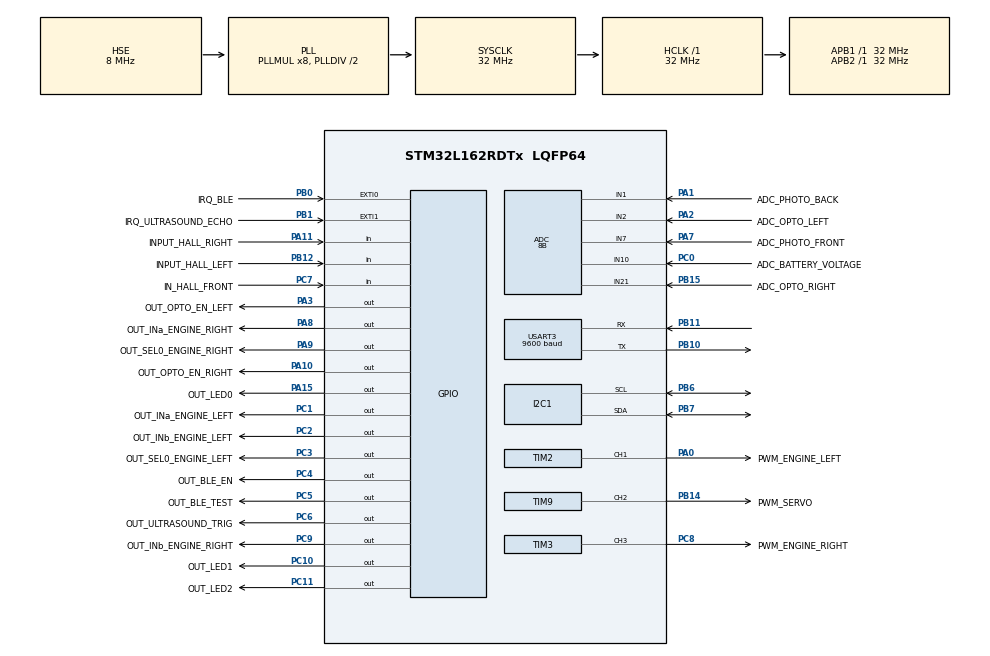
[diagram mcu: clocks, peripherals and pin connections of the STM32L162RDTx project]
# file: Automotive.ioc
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ADC.Channel-0\#ChannelRegularConversion=ADC_CHANNEL_1
ADC.NbrOfConversionFlag=1
ADC.Rank-0\#ChannelRegularConversion=1
ADC.Resolution=ADC_RESOLUTION_8B
ADC.SamplingTime-0\#ChannelRegularConversion=ADC_SAMPLETIME_4CYCLES
Dma.Request0=USART3_RX
Dma.Request1=USART3_TX
Dma.USART3_RX.0.Direction=DMA_PERIPH_TO_MEMORY
Dma.USART3_RX.0.Instance=DMA1_Channel3
Dma.USART3_RX.0.MemDataAlignment=DMA_MDATAALIGN_BYTE
Dma.USART3_RX.0.MemInc=DMA_MINC_ENABLE
Dma.USART3_RX.0.Mode=DMA_NORMAL
Dma.USART3_RX.0.PeriphDataAlignment=DMA_PDATAALIGN_BYTE
Dma.USART3_RX.0.PeriphInc=DMA_PINC_DISABLE
Dma.USART3_RX.0.Priority=DMA_PRIORITY_VERY_HIGH
Dma.USART3_TX.1.Direction=DMA_MEMORY_TO_PERIPH
Dma.USART3_TX.1.Instance=DMA1_Channel2
Dma.USART3_TX.1.MemDataAlignment=DMA_MDATAALIGN_BYTE
Dma.USART3_TX.1.MemInc=DMA_MINC_ENABLE
Dma.USART3_TX.1.Mode=DMA_NORMAL
Dma.USART3_TX.1.PeriphDataAlignment=DMA_PDATAALIGN_BYTE
Dma.USART3_TX.1.PeriphInc=DMA_PINC_DISABLE
Dma.USART3_TX.1.Priority=DMA_PRIORITY_LOW
FREERTOS.INCLUDE_xEventGroupSetBitFromISR=1
FREERTOS.Tasks01=defaultTask,24,128,StartDefaultTask,Default,NULL,Dynamic,NULL,NULL
FREERTOS.configCHECK_FOR_STACK_OVERFLOW=1
FREERTOS.configTOTAL_HEAP_SIZE=10240
FREERTOS.configUSE_DAEMON_TASK_STARTUP_HOOK=1
FREERTOS.configUSE_IDLE_HOOK=1
FREERTOS.configUSE_MALLOC_FAILED_HOOK=1
FREERTOS.configUSE_TICK_HOOK=1
I2C1.I2C_Mode=I2C_Standard
Mcu.Family=STM32L1
Mcu.Name=STM32L162RDTx
Mcu.Package=LQFP64
NVIC.ADC1_IRQn=true\:5\:0\:false\:false\:true\:true\:true\:true
NVIC.DMA1_Channel2_IRQn=true\:6\:0\:true\:false\:true\:true\:false\:true
NVIC.DMA1_Channel3_IRQn=true\:5\:0\:true\:false\:true\:true\:false\:true
NVIC.EXTI0_IRQn=true\:5\:0\:true\:false\:true\:true\:true\:true
NVIC.EXTI1_IRQn=true\:5\:0\:true\:false\:true\:true\:true\:true
NVIC.PriorityGroup=NVIC_PRIORITYGROUP_4
NVIC.TIM10_IRQn=true\:5\:0\:true\:false\:true\:true\:true\:true
NVIC.TIM5_IRQn=true\:0\:0\:false\:false\:true\:false\:false\:true
NVIC.TimeBase=TIM5_IRQn
NVIC.TimeBaseIP=TIM5
PA0-WKUP1.GPIO_Label=PWM_ENGINE_LEFT
PA0-WKUP1.Signal=S_TIM2_CH1_ETR
PA1.GPIO_Label=ADC_PHOTO_BACK
PA1.Mode=IN1
PA1.Signal=ADC_IN1
PA10.GPIO_Label=OUT_OPTO_EN_RIGHT
PA10.Signal=GPIO_Output
PA11.GPIO_Label=INPUT_HALL_RIGHT
PA11.Signal=GPIO_Input
PA13.Signal=SYS_JTMS-SWDIO
PA14.Signal=SYS_JTCK-SWCLK
PA15.GPIO_Label=OUT_LED0
PA15.Signal=GPIO_Output
PA2.GPIO_Label=ADC_OPTO_LEFT
PA2.Mode=IN2
PA2.Signal=ADC_IN2
PA3.GPIO_Label=OUT_OPTO_EN_LEFT
PA3.Signal=GPIO_Output
PA7.GPIO_Label=ADC_PHOTO_FRONT
PA7.Mode=IN7
PA7.Signal=ADC_IN7
PA8.GPIO_Label=OUT_INa_ENGINE_RIGHT
PA8.Signal=GPIO_Output
PA9.GPIO_Label=OUT_SEL0_ENGINE_RIGHT
PA9.Signal=GPIO_Output
PB0.GPIO_Label=IRQ_BLE
PB0.Signal=GPXTI0
PB1.GPIO_Label=IRQ_ULTRASOUND_ECHO
PB1.GPIO_ModeDefaultEXTI=GPIO_MODE_IT_RISING_FALLING
PB1.GPIO_PuPd=GPIO_NOPULL
PB1.Signal=GPXTI1
PB10.Mode=Asynchronous
PB10.Signal=USART3_TX
PB11.Mode=Asynchronous
PB11.Signal=USART3_RX
PB12.GPIO_Label=INPUT_HALL_LEFT
PB12.Signal=GPIO_Input
PB14.GPIO_Label=PWM_SERVO
PB14.Signal=S_TIM9_CH2
PB15.GPIO_Label=ADC_OPTO_RIGHT
PB15.Mode=IN21
PB15.Signal=ADC_IN21
PB6.Mode=I2C
PB6.Signal=I2C1_SCL
PB7.Mode=I2C
PB7.Signal=I2C1_SDA
PC0.GPIO_Label=ADC_BATTERY_VOLTAGE
PC0.Mode=IN10
PC0.Signal=ADC_IN10
PC1.GPIO_Label=OUT_INa_ENGINE_LEFT
PC1.Signal=GPIO_Output
PC10.GPIO_Label=OUT_LED1
PC10.Signal=GPIO_Output
PC11.GPIO_Label=OUT_LED2
PC11.Signal=GPIO_Output
PC2.GPIO_Label=OUT_INb_ENGINE_LEFT
PC2.Signal=GPIO_Output
PC3.GPIO_Label=OUT_SEL0_ENGINE_LEFT
PC3.Signal=GPIO_Output
PC4.GPIO_Label=OUT_BLE_EN
PC4.PinState=GPIO_PIN_SET
PC4.Signal=GPIO_Output
PC5.GPIO_Label=OUT_BLE_TEST
PC5.GPIO_PuPd=GPIO_NOPULL
PC5.Signal=GPIO_Output
PC6.GPIO_Label=OUT_ULTRASOUND_TRIG
PC6.Signal=GPIO_Output
PC7.GPIO_Label=IN_HALL_FRONT
PC7.Signal=GPIO_Input
PC8.GPIO_Label=PWM_ENGINE_RIGHT
PC8.Signal=S_TIM3_CH3
PC9.GPIO_Label=OUT_INb_ENGINE_RIGHT
PC9.Signal=GPIO_Output
PH0-OSC_IN.Mode=HSE-External-Oscillator
PH0-OSC_IN.Signal=RCC_OSC_IN
PH1-OSC_OUT.Mode=HSE-External-Oscillator
PH1-OSC_OUT.Signal=RCC_OSC_OUT
ProjectManager.HeapSize=0x200
ProjectManager.StackSize=0x400
ProjectManager.TargetToolchain=STM32CubeIDE
RCC.48MHZClocksFreq_Value=32000000
RCC.AHBFreq_Value=32000000
RCC.APB1Freq_Value=32000000
RCC.APB1TimFreq_Value=32000000
RCC.APB2Freq_Value=32000000
RCC.APB2TimFreq_Value=32000000
RCC.HCLKFreq_Value=32000000
RCC.HSE_VALUE=8000000
RCC.HSI_VALUE=16000000
RCC.LSE_VALUE=32768
RCC.MSI_VALUE=2097000
RCC.PLLMUL=RCC_PLL_MUL8
RCC.PLLSourceVirtual=RCC_PLLSOURCE_HSE
RCC.SYSCLKFreq_VALUE=32000000
RCC.SYSCLKSource=RCC_SYSCLKSOURCE_PLLCLK
RCC.VCOOutputFreq_Value=64000000
SH.S_TIM2_CH1_ETR.0=TIM2_CH1,PWM Generation1 CH1
SH.S_TIM3_CH3.0=TIM3_CH3,PWM Generation3 CH3
SH.S_TIM9_CH2.0=TIM9_CH2,PWM Generation2 CH2
TIM10.Period=1599
TIM2.AutoReloadPreload=TIM_AUTORELOAD_PRELOAD_ENABLE
TIM2.Channel-PWM\ Generation1\ CH1=TIM_CHANNEL_1
TIM2.OCFastMode_PWM-PWM\ Generation1\ CH1=TIM_OCFAST_ENABLE
TIM2.Period=3199
TIM2.Prescaler=0
TIM2.Pulse-PWM\ Generation1\ CH1=1599
TIM3.AutoReloadPreload=TIM_AUTORELOAD_PRELOAD_ENABLE
TIM3.Channel-PWM\ Generation3\ CH3=TIM_CHANNEL_3
TIM3.OCFastMode_PWM-PWM\ Generation3\ CH3=TIM_OCFAST_ENABLE
TIM3.Period=3200-1
TIM3.Pulse-PWM\ Generation3\ CH3=1500
TIM4.Period=39999
TIM4.Prescaler=3
TIM9.AutoReloadPreload=TIM_AUTORELOAD_PRELOAD_ENABLE
TIM9.Channel-PWM\ Generation2\ CH2=TIM_CHANNEL_2
TIM9.ClockDivision=TIM_CLOCKDIVISION_DIV1
TIM9.OCMode_PWM-PWM\ Generation2\ CH2=TIM_OCMODE_PWM1
TIM9.Period=3200
TIM9.Prescaler=0
TIM9.Pulse-PWM\ Generation2\ CH2=1500
USART3.BaudRate=9600
USART3.VirtualMode=VM_ASYNC
VP_FREERTOS_VS_CMSIS_V2.Mode=CMSIS_V2
VP_SYS_VS_tim5.Mode=TIM5
VP_TIM10_VS_ClockSourceINT.Mode=Internal
VP_TIM2_VS_ClockSourceINT.Mode=Internal
VP_TIM3_VS_ClockSourceINT.Mode=Internal
VP_TIM4_VS_ClockSourceINT.Mode=Internal
VP_TIM9_VS_ClockSourceINT.Mode=Internal
board=custom

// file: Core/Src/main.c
/* USER CODE BEGIN Header */
/**
 ******************************************************************************
 * @file           : main.c
 * @brief          : Main program body
 ******************************************************************************
 * @attention
 *
 * <h2><center>&copy; Copyright (c) 2021 STMicroelectronics.
 * All rights reserved.</center></h2>
 *
 * This software component is licensed by ST under Ultimate Liberty license
 * SLA0044, the "License"; You may not use this file except in compliance with
 * the License. You may obtain a copy of the License at:
 *                             www.st.com/SLA0044
 *
 ******************************************************************************
 */
/* USER CODE END Header */

#include "main.h"
#include "cmsis_os.h"
#include "adc.h"
#include "dma.h"
#include "i2c.h"
#include "tim.h"
#include "usart.h"
#include "gpio.h"

/* USER CODE BEGIN Includes */
#include "device_init.h"
#include "h_bridge.h"
/* USER CODE END Includes */

void SystemClock_Config(void);
void MX_FREERTOS_Init(void);

int main(void)
{

  /* MCU Configuration--------------------------------------------------------*/

  /* Reset of all peripherals, Initializes the Flash interface and the Systick. */
  HAL_Init();

  /* Configure the system clock */
  SystemClock_Config();

  /* Initialize all configured peripherals */
  MX_GPIO_Init();
  MX_DMA_Init();
  MX_ADC_Init();
  MX_I2C1_Init();
  MX_TIM2_Init();
  MX_TIM3_Init();
  MX_TIM9_Init();
  MX_USART3_UART_Init();
  MX_TIM4_Init();
  MX_TIM10_Init();
  /* USER CODE BEGIN 2 */
	device_init();
	h_bridge_init();
  /* USER CODE END 2 */

  /* Init scheduler */
  osKernelInitialize();  /* Call init function for freertos objects (in freertos.c) */
  MX_FREERTOS_Init();
  /* Start scheduler */
  osKernelStart();

  /* We should never get here as control is now taken by the scheduler */
  /* Infinite loop */
	while (1) {

	}
}

void SystemClock_Config(void)
{
  RCC_OscInitTypeDef RCC_OscInitStruct = {0};
  RCC_ClkInitTypeDef RCC_ClkInitStruct = {0};

  /** Configure the main internal regulator output voltage
  */
  __HAL_PWR_VOLTAGESCALING_CONFIG(PWR_REGULATOR_VOLTAGE_SCALE1);
  /** Initializes the CPU, AHB and APB busses clocks
  */
  RCC_OscInitStruct.OscillatorType = RCC_OSCILLATORTYPE_HSI|RCC_OSCILLATORTYPE_HSE;
  RCC_OscInitStruct.HSEState = RCC_HSE_ON;
  RCC_OscInitStruct.HSIState = RCC_HSI_ON;
  RCC_OscInitStruct.HSICalibrationValue = RCC_HSICALIBRATION_DEFAULT;
  RCC_OscInitStruct.PLL.PLLState = RCC_PLL_ON;
  RCC_OscInitStruct.PLL.PLLSource = RCC_PLLSOURCE_HSE;
  RCC_OscInitStruct.PLL.PLLMUL = RCC_PLL_MUL8;
  RCC_OscInitStruct.PLL.PLLDIV = RCC_PLL_DIV2;
  if (HAL_RCC_OscConfig(&RCC_OscInitStruct) != HAL_OK)
  {
    Error_Handler();
  }
  /** Initializes the CPU, AHB and APB busses clocks
  */
  RCC_ClkInitStruct.ClockType = RCC_CLOCKTYPE_HCLK|RCC_CLOCKTYPE_SYSCLK
                              |RCC_CLOCKTYPE_PCLK1|RCC_CLOCKTYPE_PCLK2;
  RCC_ClkInitStruct.SYSCLKSource = RCC_SYSCLKSOURCE_PLLCLK;
  RCC_ClkInitStruct.AHBCLKDivider = RCC_SYSCLK_DIV1;
  RCC_ClkInitStruct.APB1CLKDivider = RCC_HCLK_DIV1;
  RCC_ClkInitStruct.APB2CLKDivider = RCC_HCLK_DIV1;

  if (HAL_RCC_ClockConfig(&RCC_ClkInitStruct, FLASH_LATENCY_1) != HAL_OK)
  {
    Error_Handler();
  }
}

 /**
  * @brief  Period elapsed callback in non blocking mode
  * @note   This function is called  when TIM5 interrupt took place, inside
  * HAL_TIM_IRQHandler(). It makes a direct call to HAL_IncTick() to increment
  * a global variable "uwTick" used as application time base.
  * @param  htim : TIM handle
  * @retval None
  */
void HAL_TIM_PeriodElapsedCallback(TIM_HandleTypeDef *htim)
{
  if (htim->Instance == TIM5) {
    HAL_IncTick();
  }
  /* USER CODE BEGIN Callback 1 */

  // also the code for others timers if overflow :)

  // when tim10
  if(htim->Instance == TIM10) {
	  // clear pin ultrasound trigger
	  HAL_GPIO_WritePin(OUT_ULTRASOUND_TRIG_GPIO_Port, OUT_ULTRASOUND_TRIG_Pin, GPIO_PIN_RESET);
	  // and this is it
  }

  /* USER CODE END Callback 1 */
}

void Error_Handler(void)
{
}

/************************ (C) COPYRIGHT STMicroelectronics *****END OF FILE****/

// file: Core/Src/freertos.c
/* USER CODE BEGIN Header */
/**
  ******************************************************************************
  * File Name          : freertos.c
  * Description        : Code for freertos applications
  ******************************************************************************
  * @attention
  *
  * <h2><center>&copy; Copyright (c) 2021 STMicroelectronics.
  * All rights reserved.</center></h2>
  *
  * This software component is licensed by ST under Ultimate Liberty license
  * SLA0044, the "License"; You may not use this file except in compliance with
  * the License. You may obtain a copy of the License at:
  *                             www.st.com/SLA0044
  *
  ******************************************************************************
  */
/* USER CODE END Header */

#include "FreeRTOS.h"
#include "task.h"
#include "main.h"
#include "cmsis_os.h"

/* USER CODE BEGIN Includes */
#include "runtime.h"
/* USER CODE END Includes */

/* Definitions for defaultTask */
osThreadId_t defaultTaskHandle;
const osThreadAttr_t defaultTask_attributes = {
  .name = "defaultTask",
  .priority = (osPriority_t) osPriorityNormal,
  .stack_size = 128 * 4
};

void StartDefaultTask(void *argument);

void MX_FREERTOS_Init(void); /* (MISRA C 2004 rule 8.1) */

/* Hook prototypes */
void vApplicationIdleHook(void);
void vApplicationTickHook(void);
void vApplicationStackOverflowHook(xTaskHandle xTask, signed char *pcTaskName);
void vApplicationMallocFailedHook(void);
void vApplicationDaemonTaskStartupHook(void);

/* USER CODE BEGIN 2 */
__weak void vApplicationIdleHook( void )
{
   /* vApplicationIdleHook() will only be called if configUSE_IDLE_HOOK is set
   to 1 in FreeRTOSConfig.h. It will be called on each iteration of the idle
   task. It is essential that code added to this hook function never attempts
   to block in any way (for example, call xQueueReceive() with a block time
   specified, or call vTaskDelay()). If the application makes use of the
   vTaskDelete() API function (as this demo application does) then it is also
   important that vApplicationIdleHook() is permitted to return to its calling
   function, because it is the responsibility of the idle task to clean up
   memory allocated by the kernel to any task that has since been deleted. */
}
/* USER CODE END 2 */

/* USER CODE BEGIN 3 */
__weak void vApplicationTickHook( void )
{
   /* This function will be called by each tick interrupt if
   configUSE_TICK_HOOK is set to 1 in FreeRTOSConfig.h. User code can be
   added here, but the tick hook is called from an interrupt context, so
   code must not attempt to block, and only the interrupt safe FreeRTOS API
   functions can be used (those that end in FromISR()). */
}
/* USER CODE END 3 */

/* USER CODE BEGIN 4 */
__weak void vApplicationStackOverflowHook(xTaskHandle xTask, signed char *pcTaskName)
{
   /* Run time stack overflow checking is performed if
   configCHECK_FOR_STACK_OVERFLOW is defined to 1 or 2. This hook function is
   called if a stack overflow is detected. */
}
/* USER CODE END 4 */

/* USER CODE BEGIN 5 */
__weak void vApplicationMallocFailedHook(void)
{
   /* vApplicationMallocFailedHook() will only be called if
   configUSE_MALLOC_FAILED_HOOK is set to 1 in FreeRTOSConfig.h. It is a hook
   function that will get called if a call to pvPortMalloc() fails.
   pvPortMalloc() is called internally by the kernel whenever a task, queue,
   timer or semaphore is created. It is also called by various parts of the
   demo application. If heap_1.c or heap_2.c are used, then the size of the
   heap available to pvPortMalloc() is defined by configTOTAL_HEAP_SIZE in
   FreeRTOSConfig.h, and the xPortGetFreeHeapSize() API function can be used
   to query the size of free heap space that remains (although it does not
   provide information on how the remaining heap might be fragmented). */
}
/* USER CODE END 5 */

/* USER CODE BEGIN DAEMON_TASK_STARTUP_HOOK */
void vApplicationDaemonTaskStartupHook(void)
{
}
/* USER CODE END DAEMON_TASK_STARTUP_HOOK */

void MX_FREERTOS_Init(void) {

  /* Create the thread(s) */
  /* creation of defaultTask */
  defaultTaskHandle = osThreadNew(StartDefaultTask, NULL, &defaultTask_attributes);

  /* USER CODE BEGIN RTOS_THREADS */
  /* add threads, ... */
  rt_init();
  /* USER CODE END RTOS_THREADS */

}

void StartDefaultTask(void *argument)
{
  for(;;)
  {
    osDelay(1);
  }
}

/************************ (C) COPYRIGHT STMicroelectronics *****END OF FILE****/
